VERSION ""

NS_ :

BS_:
BU_: VCU
BO_ 2147484161 Motor: 3 VCU
   SG_ motor_mode : 0|8@1+ (1,0) [0|1] "" Vector__XXX
   SG_ torque_value : 8|16@1- (1,0) [0|1] "" Vector__XXX

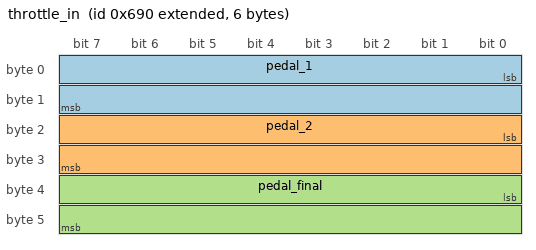
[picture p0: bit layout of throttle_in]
BO_ 2147485328 throttle_in: 6 VCU
   SG_ pedal_1 : 0|16@1+ (1,0) [0|1] "" Vector__XXX
   SG_ pedal_2 : 16|16@1+ (1,0) [0|1] "" Vector__XXX
   SG_ pedal_final : 32|16@1+ (1,0) [0|1] "" Vector__XXX

BO_ 2147485329 throttle_out: 6 VCU
   SG_ throttle_final : 0|16@1+ (1,0) [0|1] "" Vector__XXX
   SG_ throttle_torque_val : 16|16@1+ (1,0) [0|1] "" Vector__XXX

BO_ 2147485330 Msg372: 6 VCU
   SG_ fault_code : 0|8@1+ (1,0) [0|1] "" Vector__XXX
   SG_ delta : 8|32@5- (1,0) [0|1] "" Vector__XXX

BO_ 2147485331 cat_status: 6 VCU
   SG_ car_status : 0|8@1+ (1,0) [0|1] "" Vector__XXX

BA_DEF_ BO_ "GenMsgBackgroundColor" STRING ;
BA_DEF_ BO_ "GenMsgForegroundColor" STRING ;
BA_DEF_ BO_ "filterlabeling" INT 0 0;
BA_DEF_ BO_ "filterlabeling" INT 0 0;
BA_DEF_DEF_ "GenMsgBackgroundColor" "#ffffff";
BA_DEF_DEF_ "GenMsgForegroundColor" "#000000";
BA_DEF_DEF_ "filterlabeling" 1;
BA_DEF_DEF_ "filterlabeling" 1;
BA_ "GenMsgBackgroundColor" BO_ 2147484161 "#a6ffff";
BA_ "GenMsgBackgroundColor" BO_ 2147485328 "#ffc0c0";
BA_ "GenMsgBackgroundColor" BO_ 2147485329 "#c6ffbc";
BA_ "GenMsgBackgroundColor" BO_ 2147485330 "#ff0000";
BA_ "GenMsgForegroundColor" BO_ 2147485330 "#c0fffa";
BA_ "GenMsgBackgroundColor" BO_ 2147485331 "#dfdeff";
VAL_ 2147484161 motor_mode 144 "torque_command" 49 "No Description";
VAL_ 2147485330 fault_code 0 "No_fault" 1 "APPS_fault_started" 2 "APPS_fault_continuing" 3 "APPS_fault_exceeded_100ms" 4 "APPS_fault_resolved" 5 "APPS_too_low" 6 "APPS_too_high";
VAL_ 2147485331 car_status 0 "car_state_init" 1 "in_starting_sequence" 2 "buzzing" 3 "in_drive_mode";
